# PMM__Power_Management_System_6 register map
Vendor: Texas Instruments
Peripheral module from a debugger description file (folder msp430).
Registers are 16-bit, read-write, reset 0x0 unless marked. A register's access mark holds for its fields unless they carry their own. Offsets are as the file gives them; lines under a group give offsets from that group; [hi:lo] are bit positions; {n}, {i} and the like mark numbered series; 'fields as' and 'values as' point back to an identical list; <NAME> marks a mode.

## PMM_Power_Management_System
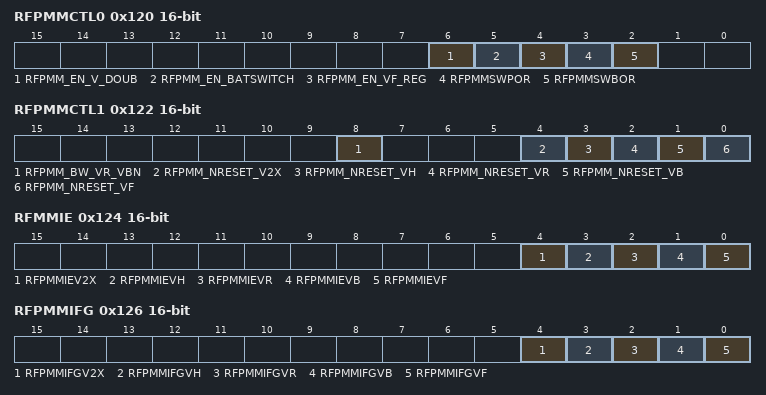
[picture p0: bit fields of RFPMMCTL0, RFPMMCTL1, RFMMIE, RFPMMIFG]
0x120 RFPMMCTL0 — RF PMM Control 0
  [6] RFPMM_EN_V_DOUB — RF PMM Enable voltage regulator for digital core. VDD
  [5] RFPMM_EN_BATSWITCH — RF PMM Enable the battery switch
  [4] RFPMM_EN_VF_REG — RF PMM Enable voltage regulator for FRAM vddf permanently
  [3] RFPMMSWPOR — RF PMM Software power-on reset. POR. Bit: 3
  [2] RFPMMSWBOR — RF MM Software brownout reset. BOR. Bit: 2
0x122 RFPMMCTL1 — RF PMM Control 1
  [8] RFPMM_BW_VR_VBN — RF PMM indicates position of the bulk switch Bit: 8
  [4] RFPMM_NRESET_V2X — RF PMM Low active reset signal of VDD2X Bit: 4
  [3] RFPMM_NRESET_VH — RF PMM Low active reset signal of VDDH Bit: 3
  [2] RFPMM_NRESET_VR — RF PMM Low active reset signal of VDDR Bit: 2
  [1] RFPMM_NRESET_VB — RF PMM Low active reset signal of VDDB Bit: 1
  [0] RFPMM_NRESET_VF — RF PMM Low active reset signal of VDDF Bit: 0
0x124 RFMMIE — RF PPM interrupt enable register
  [4] RFPMMIEV2X — RF PMM Interrupt enable voltage regulator VDD2X Bit: 4
  [3] RFPMMIEVH — RF PMM Interrupt enable voltage regulator VDDH Bit: 3
  [2] RFPMMIEVR — RF PMM Interrupt enable voltage regulator VDDR Bit: 2
  [1] RFPMMIEVB — RF PMM Interrupt enable voltage regulator VDDB Bit: 1
  [0] RFPMMIEVF — RF PMM Interrupt enable voltage regulator VDDF Bit: 0
0x126 RFPMMIFG — RF PMM Interrupt Flag
  [4] RFPMMIFGV2X — RF PMM Interrupt flag voltage regulator VDD2X Bit: 4
  [3] RFPMMIFGVH — RF PMM Interrupt flag voltage regulator VDDH Bit: 3
  [2] RFPMMIFGVR — RF PMM Interrupt flag voltage regulator VDDR Bit: 2
  [1] RFPMMIFGVB — RF PMM Interrupt flag voltage regulator VDDB Bit: 1
  [0] RFPMMIFGVF — RF PMM Interrupt flag voltage regulator VDDF Bit: 0
0x128 RFPMMIV access not given reset not defined — RF PMM Interrupt vector regiser
